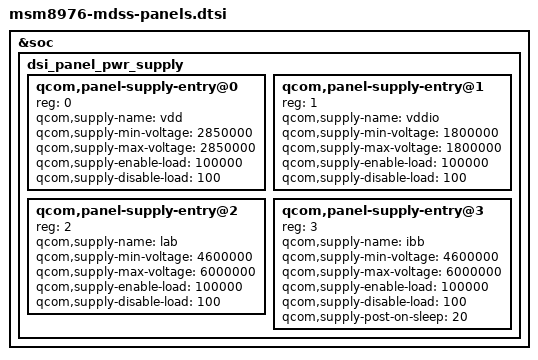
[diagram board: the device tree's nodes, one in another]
// SPDX-License-Identifier: GPL-2.0
// Copyright (c) 2015, The Linux Foundation. All rights reserved.
// Copyright (c) 2023, Benarji Anand <benarji385@gmail.com>

#include "dsi-panel-sim-video.dtsi"
#include "dsi-panel-sim-cmd.dtsi"
#include "dsi-panel-nt35597-dualmipi-wqxga-video.dtsi"
#include "dsi-panel-nt35597-dualmipi-wqxga-cmd.dtsi"
#include "dsi-panel-otm1906c-1080p-cmd.dtsi"
#include "dsi-panel-hx8399a-1080p-video.dtsi"
#include "dsi-panel-nt35597-dsc-wqxga-video.dtsi"
#include "dsi-panel-nt35597-dsc-wqxga-cmd.dtsi"
#include "dsi-panel-truly-1080p-video.dtsi"
#include "dsi-panel-tianma-nt35596-1080p-video.dtsi"
#include "dsi-panel-boe-nt35532-1080p-video.dtsi"
#include "dsi-panel-sharp-r63315-1080p-video.dtsi"
#include "dsi-panel-truly-1080p-cmd.dtsi"
#include "dsi-panel-adv7533-1080p-video.dtsi"
#include "dsi-panel-adv7533-720p-video.dtsi"
#include "dsi-panel-nt35523-dualmipi-wqxga-video.dtsi"

&soc {
	dsi_panel_pwr_supply: dsi_panel_pwr_supply {
		#address-cells = <1>;
		#size-cells = <0>;

		qcom,panel-supply-entry@0 {
			reg = <0>;
			qcom,supply-name = "vdd";
			qcom,supply-min-voltage = <2850000>;
			qcom,supply-max-voltage = <2850000>;
			qcom,supply-enable-load = <100000>;
			qcom,supply-disable-load = <100>;
		};

		qcom,panel-supply-entry@1 {
			reg = <1>;
			qcom,supply-name = "vddio";
			qcom,supply-min-voltage = <1800000>;
			qcom,supply-max-voltage = <1800000>;
			qcom,supply-enable-load = <100000>;
			qcom,supply-disable-load = <100>;
		};

		qcom,panel-supply-entry@2 {
			reg = <2>;
			qcom,supply-name = "lab";
			qcom,supply-min-voltage = <4600000>;
			qcom,supply-max-voltage = <6000000>;
			qcom,supply-enable-load = <100000>;
			qcom,supply-disable-load = <100>;
		};

		qcom,panel-supply-entry@3 {
			reg = <3>;
			qcom,supply-name = "ibb";
			qcom,supply-min-voltage = <4600000>;
			qcom,supply-max-voltage = <6000000>;
			qcom,supply-enable-load = <100000>;
			qcom,supply-disable-load = <100>;
			qcom,supply-post-on-sleep = <20>;
		};
	};
};
